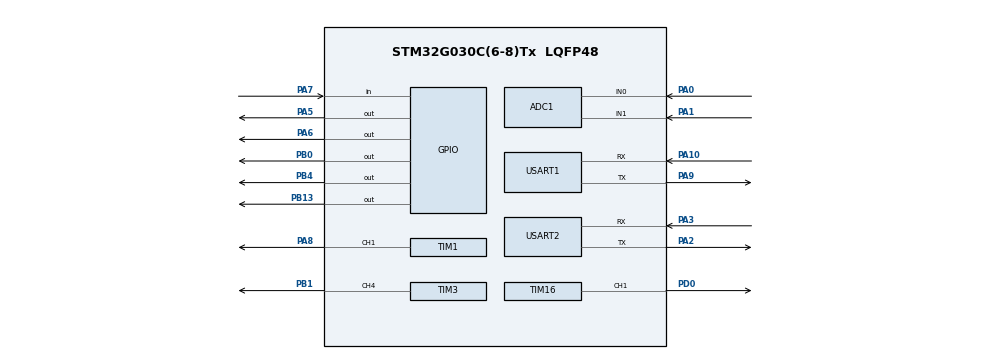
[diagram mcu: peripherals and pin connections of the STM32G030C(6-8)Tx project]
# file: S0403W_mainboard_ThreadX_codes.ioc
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ADC1.Channel-0\#ChannelRegularConversion=ADC_CHANNEL_0
ADC1.NbrOfConversionFlag=1
ADC1.Rank-0\#ChannelRegularConversion=1
ADC1.SamplingTime-0\#ChannelRegularConversion=ADC_SAMPLINGTIME_COMMON_1
ADC1.SelectedChannel=ADC_CHANNEL_0|ADC_CHANNEL_1
ADC1.master=1
Dma.ADC1.4.Direction=DMA_PERIPH_TO_MEMORY
Dma.ADC1.4.EventEnable=DISABLE
Dma.ADC1.4.Instance=DMA1_Channel5
Dma.ADC1.4.MemDataAlignment=DMA_MDATAALIGN_HALFWORD
Dma.ADC1.4.MemInc=DMA_MINC_ENABLE
Dma.ADC1.4.Mode=DMA_NORMAL
Dma.ADC1.4.PeriphDataAlignment=DMA_PDATAALIGN_HALFWORD
Dma.ADC1.4.PeriphInc=DMA_PINC_DISABLE
Dma.ADC1.4.Polarity=HAL_DMAMUX_REQ_GEN_RISING
Dma.ADC1.4.Priority=DMA_PRIORITY_LOW
Dma.ADC1.4.RequestNumber=1
Dma.ADC1.4.SignalID=NONE
Dma.ADC1.4.SyncEnable=DISABLE
Dma.ADC1.4.SyncPolarity=HAL_DMAMUX_SYNC_NO_EVENT
Dma.ADC1.4.SyncRequestNumber=1
Dma.ADC1.4.SyncSignalID=NONE
Dma.Request0=USART1_RX
Dma.Request1=USART1_TX
Dma.Request2=USART2_RX
Dma.Request3=USART2_TX
Dma.Request4=ADC1
Dma.USART1_RX.0.Direction=DMA_PERIPH_TO_MEMORY
Dma.USART1_RX.0.EventEnable=DISABLE
Dma.USART1_RX.0.Instance=DMA1_Channel1
Dma.USART1_RX.0.MemDataAlignment=DMA_MDATAALIGN_BYTE
Dma.USART1_RX.0.MemInc=DMA_MINC_ENABLE
Dma.USART1_RX.0.Mode=DMA_NORMAL
Dma.USART1_RX.0.PeriphDataAlignment=DMA_PDATAALIGN_BYTE
Dma.USART1_RX.0.PeriphInc=DMA_PINC_DISABLE
Dma.USART1_RX.0.Polarity=HAL_DMAMUX_REQ_GEN_RISING
Dma.USART1_RX.0.Priority=DMA_PRIORITY_LOW
Dma.USART1_RX.0.RequestNumber=1
Dma.USART1_RX.0.SignalID=NONE
Dma.USART1_RX.0.SyncEnable=DISABLE
Dma.USART1_RX.0.SyncPolarity=HAL_DMAMUX_SYNC_NO_EVENT
Dma.USART1_RX.0.SyncRequestNumber=1
Dma.USART1_RX.0.SyncSignalID=NONE
Dma.USART1_TX.1.Direction=DMA_MEMORY_TO_PERIPH
Dma.USART1_TX.1.EventEnable=DISABLE
Dma.USART1_TX.1.Instance=DMA1_Channel2
Dma.USART1_TX.1.MemDataAlignment=DMA_MDATAALIGN_BYTE
Dma.USART1_TX.1.MemInc=DMA_MINC_ENABLE
Dma.USART1_TX.1.Mode=DMA_NORMAL
Dma.USART1_TX.1.PeriphDataAlignment=DMA_PDATAALIGN_BYTE
Dma.USART1_TX.1.PeriphInc=DMA_PINC_DISABLE
Dma.USART1_TX.1.Polarity=HAL_DMAMUX_REQ_GEN_RISING
Dma.USART1_TX.1.Priority=DMA_PRIORITY_LOW
Dma.USART1_TX.1.RequestNumber=1
Dma.USART1_TX.1.SignalID=NONE
Dma.USART1_TX.1.SyncEnable=DISABLE
Dma.USART1_TX.1.SyncPolarity=HAL_DMAMUX_SYNC_NO_EVENT
Dma.USART1_TX.1.SyncRequestNumber=1
Dma.USART1_TX.1.SyncSignalID=NONE
Dma.USART2_RX.2.Direction=DMA_PERIPH_TO_MEMORY
Dma.USART2_RX.2.EventEnable=DISABLE
Dma.USART2_RX.2.Instance=DMA1_Channel3
Dma.USART2_RX.2.MemDataAlignment=DMA_MDATAALIGN_BYTE
Dma.USART2_RX.2.MemInc=DMA_MINC_ENABLE
Dma.USART2_RX.2.Mode=DMA_NORMAL
Dma.USART2_RX.2.PeriphDataAlignment=DMA_PDATAALIGN_BYTE
Dma.USART2_RX.2.PeriphInc=DMA_PINC_DISABLE
Dma.USART2_RX.2.Polarity=HAL_DMAMUX_REQ_GEN_RISING
Dma.USART2_RX.2.Priority=DMA_PRIORITY_LOW
Dma.USART2_RX.2.RequestNumber=1
Dma.USART2_RX.2.SignalID=NONE
Dma.USART2_RX.2.SyncEnable=DISABLE
Dma.USART2_RX.2.SyncPolarity=HAL_DMAMUX_SYNC_NO_EVENT
Dma.USART2_RX.2.SyncRequestNumber=1
Dma.USART2_RX.2.SyncSignalID=NONE
Dma.USART2_TX.3.Direction=DMA_MEMORY_TO_PERIPH
Dma.USART2_TX.3.EventEnable=DISABLE
Dma.USART2_TX.3.Instance=DMA1_Channel4
Dma.USART2_TX.3.MemDataAlignment=DMA_MDATAALIGN_BYTE
Dma.USART2_TX.3.MemInc=DMA_MINC_ENABLE
Dma.USART2_TX.3.Mode=DMA_NORMAL
Dma.USART2_TX.3.PeriphDataAlignment=DMA_PDATAALIGN_BYTE
Dma.USART2_TX.3.PeriphInc=DMA_PINC_DISABLE
Dma.USART2_TX.3.Polarity=HAL_DMAMUX_REQ_GEN_RISING
Dma.USART2_TX.3.Priority=DMA_PRIORITY_LOW
Dma.USART2_TX.3.RequestNumber=1
Dma.USART2_TX.3.SignalID=NONE
Dma.USART2_TX.3.SyncEnable=DISABLE
Dma.USART2_TX.3.SyncPolarity=HAL_DMAMUX_SYNC_NO_EVENT
Dma.USART2_TX.3.SyncRequestNumber=1
Dma.USART2_TX.3.SyncSignalID=NONE
Mcu.Family=STM32G0
Mcu.Name=STM32G030C(6-8)Tx
Mcu.Package=LQFP48
NVIC.DMA1_Ch4_5_DMAMUX1_OVR_IRQn=true\:0\:0\:false\:false\:true\:true\:false\:true\:true
NVIC.DMA1_Channel1_IRQn=true\:0\:0\:false\:false\:true\:true\:false\:true\:true
NVIC.DMA1_Channel2_3_IRQn=true\:0\:0\:false\:false\:true\:true\:false\:true\:true
NVIC.TIM14_IRQn=true\:3\:0\:false\:false\:true\:false\:false\:true\:true
NVIC.TIM17_IRQn=true\:0\:0\:false\:false\:true\:false\:true\:true\:true
NVIC.TimeBase=TIM14_IRQn
NVIC.TimeBaseIP=TIM14
NVIC.USART1_IRQn=true\:0\:0\:false\:false\:true\:false\:true\:true\:true
NVIC.USART2_IRQn=true\:0\:0\:false\:false\:true\:false\:false\:true\:true
PA0.Mode=IN0
PA0.Signal=ADC1_IN0
PA1.Mode=IN1
PA1.Signal=ADC1_IN1
PA10.Mode=Asynchronous
PA10.Signal=USART1_RX
PA13.Mode=Serial_Wire
PA13.Signal=SYS_SWDIO
PA14-BOOT0.Mode=Serial_Wire
PA14-BOOT0.Signal=SYS_SWCLK
PA2.Mode=Asynchronous
PA2.Signal=USART2_TX
PA3.Mode=Asynchronous
PA3.Signal=USART2_RX
PA5.Signal=GPIO_Output
PA6.Signal=GPIO_Output
PA7.Signal=GPIO_Input
PA8.Signal=S_TIM1_CH1
PA9.Mode=Asynchronous
PA9.Signal=USART1_TX
PB0.Signal=GPIO_Output
PB1.Signal=S_TIM3_CH4
PB13.Signal=GPIO_Output
PB4.Signal=GPIO_Output
PD0.Signal=S_TIM16_CH1
ProjectManager.HeapSize=0x200
ProjectManager.StackSize=0x400
ProjectManager.TargetToolchain=MDK-ARM V5.32
RCC.ADCFreq_Value=64000000
RCC.AHBFreq_Value=64000000
RCC.CortexFreq_Value=64000000
RCC.EXTERNAL_CLOCK_VALUE=12288000
RCC.HCLKFreq_Value=64000000
RCC.HSE_VALUE=8000000
RCC.HSI_VALUE=16000000
RCC.LSE_VALUE=32768
RCC.SYSCLKFreq_VALUE=64000000
RCC.SYSCLKSource=RCC_SYSCLKSOURCE_PLLCLK
RCC.VCOOutputFreq_Value=128000000
SH.S_TIM16_CH1.0=TIM16_CH1,PWM Generation1 CH1
SH.S_TIM1_CH1.0=TIM1_CH1,PWM Generation1 CH1
SH.S_TIM3_CH4.0=TIM3_CH4,PWM Generation4 CH4
STMicroelectronics.X-CUBE-AZRTOS-G0.1.1.0.ThreadXCcRTOSJjThreadXJjCore=true
STMicroelectronics.X-CUBE-AZRTOS-G0.1.1.0_IsAnAzureRtosMw=true
TIM1.Channel-PWM\ Generation1\ CH1=TIM_CHANNEL_1
TIM16.Channel=TIM_CHANNEL_1
TIM3.Channel-PWM\ Generation4\ CH4=TIM_CHANNEL_4
USART1.VirtualMode-Asynchronous=VM_ASYNC
USART2.VirtualMode-Asynchronous=VM_ASYNC
VP_STMicroelectronics.X-CUBE-AZRTOS-G0_VS_RTOSJjThreadX_6.1.10_1.1.0.Mode=RTOSJjThreadX
VP_SYS_VS_tim14.Mode=TIM14
VP_TIM16_VS_ClockSourceINT.Mode=Enable_Timer
VP_TIM17_VS_ClockSourceINT.Mode=Enable_Timer
board=custom

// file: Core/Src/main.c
/* USER CODE BEGIN Header */
/**
  ******************************************************************************
  * @file           : main.c
  * @brief          : Main program body
  ******************************************************************************
  * @attention
  *
  * version: 1.0  compatible older and new PCB .in "main.h"
  *    #define NEW_PCB  ON/OFF.DATA.2026-04-07
  *  data:2026-04-21 : add auto check wifi is not connect is success .
  *                    reconnect wifi function .
  *
  *
  *
  *
  ******************************************************************************
  */
/* USER CODE END Header */
#include "main.h"
#include "adc.h"
#include "dma.h"
#include "iwdg.h"
#include "tim.h"
#include "usart.h"
#include "gpio.h"

/* USER CODE BEGIN Includes */
#include "bsp.h"
/* USER CODE END Includes */

void SystemClock_Config(void);

int main(void)
{

  /* MCU Configuration--------------------------------------------------------*/

  /* Reset of all peripherals, Initializes the Flash interface and the Systick. */
  HAL_Init();

  /* Configure the system clock */
  SystemClock_Config();

  /* Initialize all configured peripherals */
  MX_GPIO_Init();
  MX_DMA_Init();
  MX_TIM16_Init();
  MX_USART1_UART_Init();
  MX_USART2_UART_Init();
  MX_ADC1_Init();
  MX_TIM1_Init();
  MX_TIM3_Init();
  MX_TIM17_Init();
  MX_IWDG_Init();
  /* USER CODE BEGIN 2 */
  LL_IWDG_ReloadCounter(IWDG);
    bsp_init();
  /* USER CODE END 2 */

  /* Infinite loop */
  while (1)
  {

    /* USER CODE BEGIN 3 */
	task_handler();
  }
  /* USER CODE END 3 */
}

void SystemClock_Config(void)
{
  LL_FLASH_SetLatency(LL_FLASH_LATENCY_2);
  while(LL_FLASH_GetLatency() != LL_FLASH_LATENCY_2)
  {
  }

  /* HSI configuration and activation */
  LL_RCC_HSI_Enable();
  while(LL_RCC_HSI_IsReady() != 1)
  {
  }

  /* LSI configuration and activation */
  LL_RCC_LSI_Enable();
  while(LL_RCC_LSI_IsReady() != 1)
  {
  }

  /* Main PLL configuration and activation */
  LL_RCC_PLL_ConfigDomain_SYS(LL_RCC_PLLSOURCE_HSI, LL_RCC_PLLM_DIV_1, 8, LL_RCC_PLLR_DIV_2);
  LL_RCC_PLL_Enable();
  LL_RCC_PLL_EnableDomain_SYS();
  while(LL_RCC_PLL_IsReady() != 1)
  {
  }

  /* Set AHB prescaler*/
  LL_RCC_SetAHBPrescaler(LL_RCC_SYSCLK_DIV_1);

  /* Sysclk activation on the main PLL */
  LL_RCC_SetSysClkSource(LL_RCC_SYS_CLKSOURCE_PLL);
  while(LL_RCC_GetSysClkSource() != LL_RCC_SYS_CLKSOURCE_STATUS_PLL)
  {
  }

  /* Set APB1 prescaler*/
  LL_RCC_SetAPB1Prescaler(LL_RCC_APB1_DIV_1);
  /* Update CMSIS variable (which can be updated also through SystemCoreClockUpdate function) */
  LL_SetSystemCoreClock(64000000);

   /* Update the time base */
  if (HAL_InitTick (TICK_INT_PRIORITY) != HAL_OK)
  {
    Error_Handler();
  }
}

void Error_Handler(void)
{
  __disable_irq();
  while (1)
  {
  }
}
